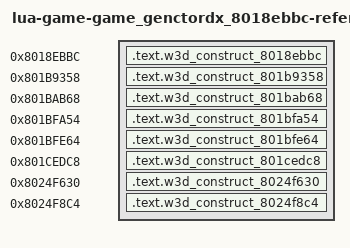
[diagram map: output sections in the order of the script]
/* Generated reference-only placements. All bodies are source-built. */
OUTPUT_FORMAT("elf32-powerpc")
OUTPUT_ARCH(powerpc)
ENTRY(w3d_construct_8018ebbc)
_SDA_BASE_ = 0x804b2540;
_SDA2_BASE_ = 0x804c2540;
fn_8018e26c = 0x8018e26c;
fn_801b8bf8 = 0x801b8bf8;
fn_801b9110 = 0x801b9110;
fn_801bf6a4 = 0x801bf6a4;
fn_801bfc38 = 0x801bfc38;
fn_801cec1c = 0x801cec1c;
fn_801ea0ec = 0x801ea0ec;
lbl_803a8074 = 0x803a8074;
lbl_803ab484 = 0x803ab484;
lbl_803ab5e0 = 0x803ab5e0;
lbl_803ac0d8 = 0x803ac0d8;
lbl_803ac0dc = 0x803ac0dc;
lbl_803ac240 = 0x803ac240;
lbl_803ac244 = 0x803ac244;
lbl_803aede4 = 0x803aede4;
lbl_803aede8 = 0x803aede8;
lbl_803c561c = 0x803c561c;
lbl_803c56c8 = 0x803c56c8;
lbl_80413110 = 0x80413110;
lbl_80414ee8 = 0x80414ee8;
lbl_80414f38 = 0x80414f38;
lbl_804154d8 = 0x804154d8;
lbl_80415690 = 0x80415690;
lbl_80415da8 = 0x80415da8;
lbl_8041b6e0 = 0x8041b6e0;
lbl_8041b708 = 0x8041b708;
SECTIONS {
  .text.w3d_construct_8018ebbc 0x8018ebbc : { *(.text.w3d_construct_8018ebbc) }
  .text.w3d_construct_801b9358 0x801b9358 : { *(.text.w3d_construct_801b9358) }
  .text.w3d_construct_801bab68 0x801bab68 : { *(.text.w3d_construct_801bab68) }
  .text.w3d_construct_801bfa54 0x801bfa54 : { *(.text.w3d_construct_801bfa54) }
  .text.w3d_construct_801bfe64 0x801bfe64 : { *(.text.w3d_construct_801bfe64) }
  .text.w3d_construct_801cedc8 0x801cedc8 : { *(.text.w3d_construct_801cedc8) }
  .text.w3d_construct_8024f630 0x8024f630 : { *(.text.w3d_construct_8024f630) }
  .text.w3d_construct_8024f8c4 0x8024f8c4 : { *(.text.w3d_construct_8024f8c4) }
  /DISCARD/ : { *(.text*) *(.rodata*) *(.data*) *(.bss*) *(.sdata*) *(.sbss*) *(.comment) }
}
